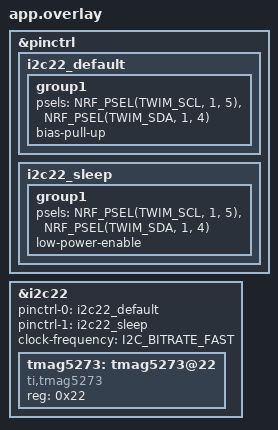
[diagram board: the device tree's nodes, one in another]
#include <zephyr/dt-bindings/pinctrl/nrf-pinctrl.h>
&pinctrl {
i2c22_default: i2c22_default {
group1 {
psels = <NRF_PSEL(TWIM_SCL, 1, 5)>,
<NRF_PSEL(TWIM_SDA, 1, 4)>;
bias-pull-up;
};
};

i2c22_sleep: i2c22_sleep {
group1 {
psels = <NRF_PSEL(TWIM_SCL, 1, 5)>,
<NRF_PSEL(TWIM_SDA, 1, 4)>;
low-power-enable;
};
};
};

&i2c22 {
status = "okay";
pinctrl-0 = <&i2c22_default>;
pinctrl-1 = <&i2c22_sleep>;
pinctrl-names = "default", "sleep";
clock-frequency = <I2C_BITRATE_FAST>;

tmag5273: tmag5273@22 {
compatible = "ti,tmag5273";
reg = <0x22>;
status = "okay";

};
};
